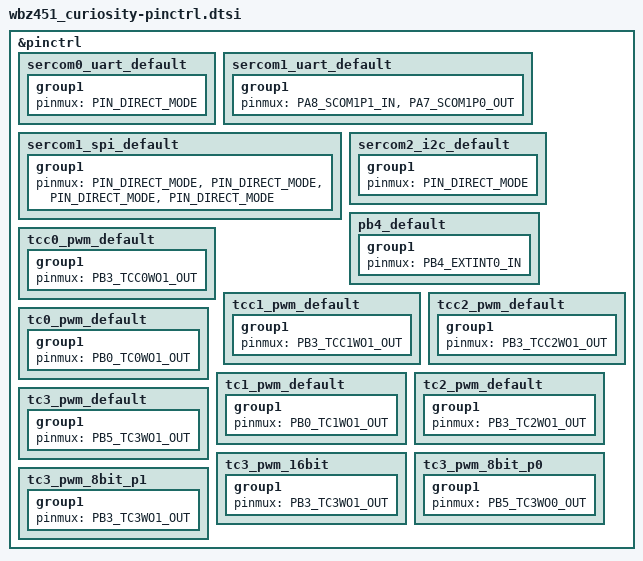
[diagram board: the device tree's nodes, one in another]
/*
 * Copyright (c) 2025 Microchip Technology Inc.
 *
 * SPDX-License-Identifier: Apache-2.0
 */

#include <dt-bindings/pic32c/pic32cx_bz/bz25/pic32cx1012bz25048-pinctrl.h>

&pinctrl {
	sercom0_uart_default: sercom0_uart_default {
		group1 {
			pinmux = <PIN_DIRECT_MODE>;
		};
	};

	sercom1_uart_default: sercom1_uart_default {
		group1 {
			pinmux = <PA8_SCOM1P1_IN>,
				<PA7_SCOM1P0_OUT>;
		};
	};

	sercom1_spi_default: sercom1_spi_default {
		group1 {
			pinmux = <PIN_DIRECT_MODE>,
				<PIN_DIRECT_MODE>,
				<PIN_DIRECT_MODE>,
				<PIN_DIRECT_MODE>;
		};
	};

	sercom2_i2c_default: sercom2_i2c_default {
		group1 {
			pinmux = <PIN_DIRECT_MODE>;
		};
	};

	pb4_default: pb4_default{
		group1 {
			pinmux = <PB4_EXTINT0_IN>;
		};
	};

	tcc0_pwm_default: tcc0_pwm_default {
		group1 {
			pinmux = <PB3_TCC0WO1_OUT>;
		};
	};

	tcc1_pwm_default: tcc1_pwm_default {
		group1 {
			pinmux = <PB3_TCC1WO1_OUT>;
		};
	};

	tcc2_pwm_default: tcc2_pwm_default {
		group1 {
			pinmux = <PB3_TCC2WO1_OUT>;
		};
	};

	tc0_pwm_default: tc0_pwm_default {
		group1 {
			pinmux = <PB0_TC0WO1_OUT>;
		};
	};

	tc1_pwm_default: tc1_pwm_default {
		group1 {
			pinmux = <PB0_TC1WO1_OUT>;
		};
	};

	tc2_pwm_default: tc2_pwm_default {
		group1 {
			pinmux = <PB3_TC2WO1_OUT>;
		};
	};

	tc3_pwm_default: tc3_pwm_default {
		group1 {
			pinmux = <PB5_TC3WO1_OUT>;
		};
	};


	tc3_pwm_16bit: tc3_pwm_16bit {
		group1 {
			pinmux = <PB3_TC3WO1_OUT>;
		};
	};

	tc3_pwm_8bit_p0: tc3_pwm_8bit_p0 {
		group1 {
			pinmux = <PB5_TC3WO0_OUT>;
		};
	};

	tc3_pwm_8bit_p1: tc3_pwm_8bit_p1 {
		group1 {
			pinmux = <PB3_TC3WO1_OUT>;
		};
	};
};
